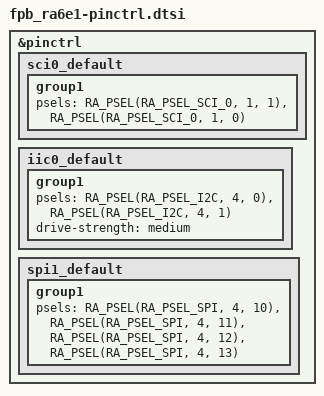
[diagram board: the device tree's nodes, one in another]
/*
 * Copyright (c) 2024 Renesas Electronics Corporation
 * SPDX-License-Identifier: Apache-2.0
 */

&pinctrl {
	sci0_default: sci0_default {
		group1 {
			/* tx rx */
			psels = <RA_PSEL(RA_PSEL_SCI_0, 1, 1)>,
			<RA_PSEL(RA_PSEL_SCI_0, 1, 0)>;
		};
	};

	iic0_default: iic0_default {
		group1 {
			/* SCL0 SDA0 */
			psels = <RA_PSEL(RA_PSEL_I2C, 4, 0)>,
			<RA_PSEL(RA_PSEL_I2C, 4, 1)>;
			drive-strength = "medium";
		};
	};

	spi1_default: spi1_default {
		group1 {
			/* MISO MOSI RSPCK SSL */
			psels = <RA_PSEL(RA_PSEL_SPI, 4, 10)>,
			<RA_PSEL(RA_PSEL_SPI, 4, 11)>,
			<RA_PSEL(RA_PSEL_SPI, 4, 12)>,
			<RA_PSEL(RA_PSEL_SPI, 4, 13)>;
		};
	};
};
